# nrf7140_sysctrl register map
Vendor: Nordic Semiconductor; Series: nRF71; File version: 1
Registers are 32-bit, read-write, reset 0x0 unless marked. A register's access mark holds for its fields unless they carry their own. Offsets are from the block's base; [hi:lo] are bit positions; lines under a group give offsets from that group; {n}, {i} and the like mark numbered series.

## PPIB110 — PPIB APB registers 0
Base 0x5F098000
Same registers: PPIB120 0x5F8EE000, PPIB121 0x5F8EF000, PPIB130 0x5F925000, PPIB131 0x5F926000, PPIB132 0x5F98D000, PPIB133 0x5F99D000, PPIB134 0x5F9AD000, PPIB135 0x5F9BD000, PPIB136 0x5F9CD000, PPIB137 0x5F9DD000
{0x0+4i} TASKS_SEND[{i}] (i=0..31) wo — Description collection: This task is unused, but the PPIB provides the SUBSCRIBE task to connect SEND [n] task.
  [0] TASKS_SEND — This task is unused, but the PPIB provides the SUBSCRIBE task to connect SEND [n] task.
    1=Trigger task
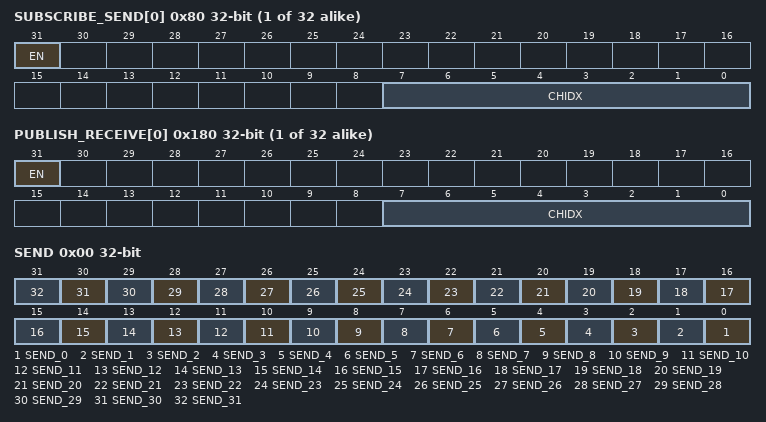
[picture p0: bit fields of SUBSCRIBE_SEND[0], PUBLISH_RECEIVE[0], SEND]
{0x80+4i} SUBSCRIBE_SEND[{i}] (i=0..31) — Description collection: Subscribe configuration for task SEND[n]
  [31] EN
    0=Disabled (Disable subscription); 1=Enabled (Enable subscription)
  [7:0] CHIDX — DPPI channel that task SEND[n] will subscribe to
{0x100+4i} EVENTS_RECEIVE[{i}] (i=0..31) — Description collection: This event is unused, but the PPIB provides the PUBLISH event to connect RECEIVE [n] event.
  [0] EVENTS_RECEIVE — This event is unused, but the PPIB provides the PUBLISH event to connect RECEIVE [n] event.
    0=NotGenerated (Event not generated); 1=Generated (Event generated)
{0x180+4i} PUBLISH_RECEIVE[{i}] (i=0..31) — Description collection: Publish configuration for event RECEIVE[n]
  [31] EN
    0=Disabled (Disable publishing); 1=Enabled (Enable publishing)
  [7:0] CHIDX — DPPI channel that event RECEIVE[n] will publish to
0x400 OVERFLOW group — Unspecified
  0x00 SEND — The task overflow for SEND tasks using SUBSCRIBE_SEND. Write 0 to clear.
    [all] fields
      1=Overflow (Task overflow is happened.); 0=NoOverflow (Task overflow is not happened.)
    [n] SEND_{n} (n=0..31) — The status for tasks overflow at SUBSCRIBE_SEND[{n}].

## ROMC — ROM Controller
Base 0x5F8C6000
0x500 POWER group — Unspecified
  0x00 CONTROL reset 0x1 — ROM power control register.
    [0] MEM0 — Keep the ROM block MEM[0] on or off when in System ON mode.
      0=Off (Power down); 1=On (Power up)

## RESETINFO120 — RESETINFO 0
Base 0x5F8CE000; alternate view of LRCCONF120
Same registers: RESETINFO130 0x5F93E000 (alternate view of LRCCONF130)
0x4A0 RESETREAS group — Unspecified
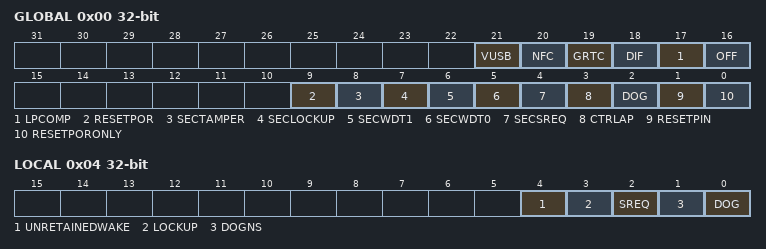
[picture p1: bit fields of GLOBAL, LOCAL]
  0x00 GLOBAL — Global reset reason.
    [all] fields
      0=NotDetected; 1=Detected
    [21] VUSB — Reset after wakeup from System OFF mode due to VBUS rising into valid range.
    [20] NFC — Reset due to wakeup from System OFF mode when wakeup is triggered by NFC field detection in sense mode.
    [19] GRTC — Reset due to wakeup from System OFF mode when wakeup is triggered by GRTC interrupt.
    [18] DIF — Reset due to wakeup from System OFF mode when wakeup is triggered by entering the debug interface mode.
    [17] LPCOMP — Reset due to wakeup from System OFF mode when wakeup is triggered by LPCOMP (Low Power Comparator).
    [16] OFF — Reset due to wakeup from System OFF mode when wakeup is triggered by DETECT signal from GPIO.
    [9] RESETPOR — Reset from power on reset (reset reason other than POR or BOR).
    [8] SECTAMPER — Reset due to secure domain tamper detected
    [7] SECLOCKUP — Reset due to secure domain lockup.
    [6] SECWDT1 — Reset due to the second instance of watchdog timer in secure domain detected.
    [5] SECWDT0 — Reset due to the first instance of watchdog timer in secure domain detected.
    [4] SECSREQ — Reset due to secure domain system reset request.
    [3] CTRLAP — Reset from CTRL-AP detected.
    [2] DOG — Reset from the SysCtrl watchdog timer detected.
    [1] RESETPIN — Reset from pin reset detected.
    [0] RESETPORONLY — Reset from power on reset (reset reason POR or BOR).
  0x04 LOCAL — Local reset reason.
    [4] UNRETAINEDWAKE — Reset due to wake from unretained state.
    [3] LOCKUP — Reset from local CPU lockup detected
      0=NotDetected; 1=Detected
    [2] SREQ — Reset from the local soft reset request detected.
      0=NotDetected; 1=Detected
    [1] DOGNS — Reset from the local non-secure watchdog timer detected
      0=NotDetected; 1=Detected
    [0] DOG — Reset from the local watchdog timer detected
      0=NotDetected; 1=Detected
0x4A8 ERROR group — Unspecified
  0x00 STATUS — Reset error status.
    [3:0] ERRORSTATUS
  0x04 ADDRESS — Reset error address.
    [31:0] ERRORADDRESS
0x4C0 RESTOREVALID — Valid restore image is present in RAM.
  [0] RESTOREVALID
    0=NotPreset (Not present); 1=Present
0x4C4 MASKLOCKUP — Mask CPU lockup signal.
  [0] MASK — Mask lockup signal
    0=NotMask (Do not mask lockup signal); 1=Mask lockup signal
